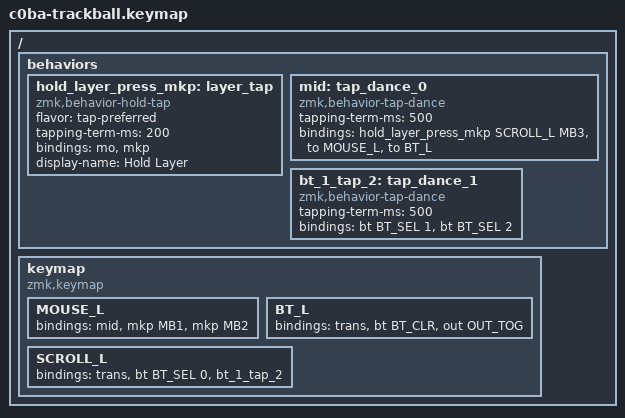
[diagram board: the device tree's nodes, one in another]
/*
    No chosen zmk,matrix-transform here if using ZMK stuidio.
    https://zmk.dev/docs/features/studio#adding-zmk-studio-support-to-a-keyboard

    Put trackball listener here and place input-processors inside!
*/

#include <input/processors.dtsi>
#include <dt-bindings/zmk/mouse.h>
#include <dt-bindings/zmk/input_transform.h>
#include <zephyr/dt-bindings/input/input-event-codes.h>
#include <behaviors.dtsi>
#include <dt-bindings/zmk/bt.h>
#include <dt-bindings/zmk/keys.h>
#include <dt-bindings/zmk/outputs.h>
#include <dt-bindings/zmk/pointing.h>

// keep all behavior settings for zmk studio
#define ZMK_BEHAVIORS_OMIT_KT

// layers

#define MOUSE_L		0
#define BT_L 		1
#define SCROLL_L 	2

// Mouse speed increased
#define ZMK_POINTING_DEFAULT_MOVE_VAL 1000  // default: 600
#define ZMK_POINTING_DEFAULT_SCRL_VAL 15    // default: 10
//#include <dt-bindings/zmk/pointing.h>


/ {
	behaviors {
		hold_layer_press_mkp: layer_tap {
            		compatible = "zmk,behavior-hold-tap";
            		#binding-cells = <2>;
            		flavor = "tap-preferred";
            		tapping-term-ms = <200>;
            		bindings = <&mo>, <&mkp>;
            		display-name = "Hold Layer";
        	};
        	mid: tap_dance_0 {
            		compatible = "zmk,behavior-tap-dance";
            		#binding-cells = <0>;
            		tapping-term-ms = <500>;
            		bindings = <&hold_layer_press_mkp SCROLL_L MB3>, <&to MOUSE_L>, <&to BT_L>;
        	};
        	bt_1_tap_2: tap_dance_1 {
            		compatible = "zmk,behavior-tap-dance";
            		#binding-cells = <0>;
            		tapping-term-ms = <500>;
            		bindings = <&bt BT_SEL 1>, <&bt BT_SEL 2>;
        	};
	};
	keymap {
                compatible = "zmk,keymap";

/* 0 */         MOUSE_L {
				/* MOUSE
				 * -----------------
				 * |       |   MMB   | 
				 * | LMB   |   RMB   |
				 */
                        bindings = <
						&mid
				&mkp MB1        &mkp MB2
                        >;
                };

/* 1 */         BT_L {
				/* BlueTooth setup layer
				 * -----------------
				 * |          |   MMB             | 
				 * | BT_CLR   |   USB_BT_TOGGLE   |
				 */
                        bindings = <
						&trans
				&bt BT_CLR	&out  OUT_TOG
                        >;
                };
	
/* 2 */         SCROLL_L {
				/* SCROLL
				 * -----------------
				 * |       |   MMB   | 
				 * | BT 1  |   BT 2  |
				 */
                        bindings = <
						&trans
				&bt BT_SEL 0        &bt_1_tap_2
                        >;
                };
        };
};
